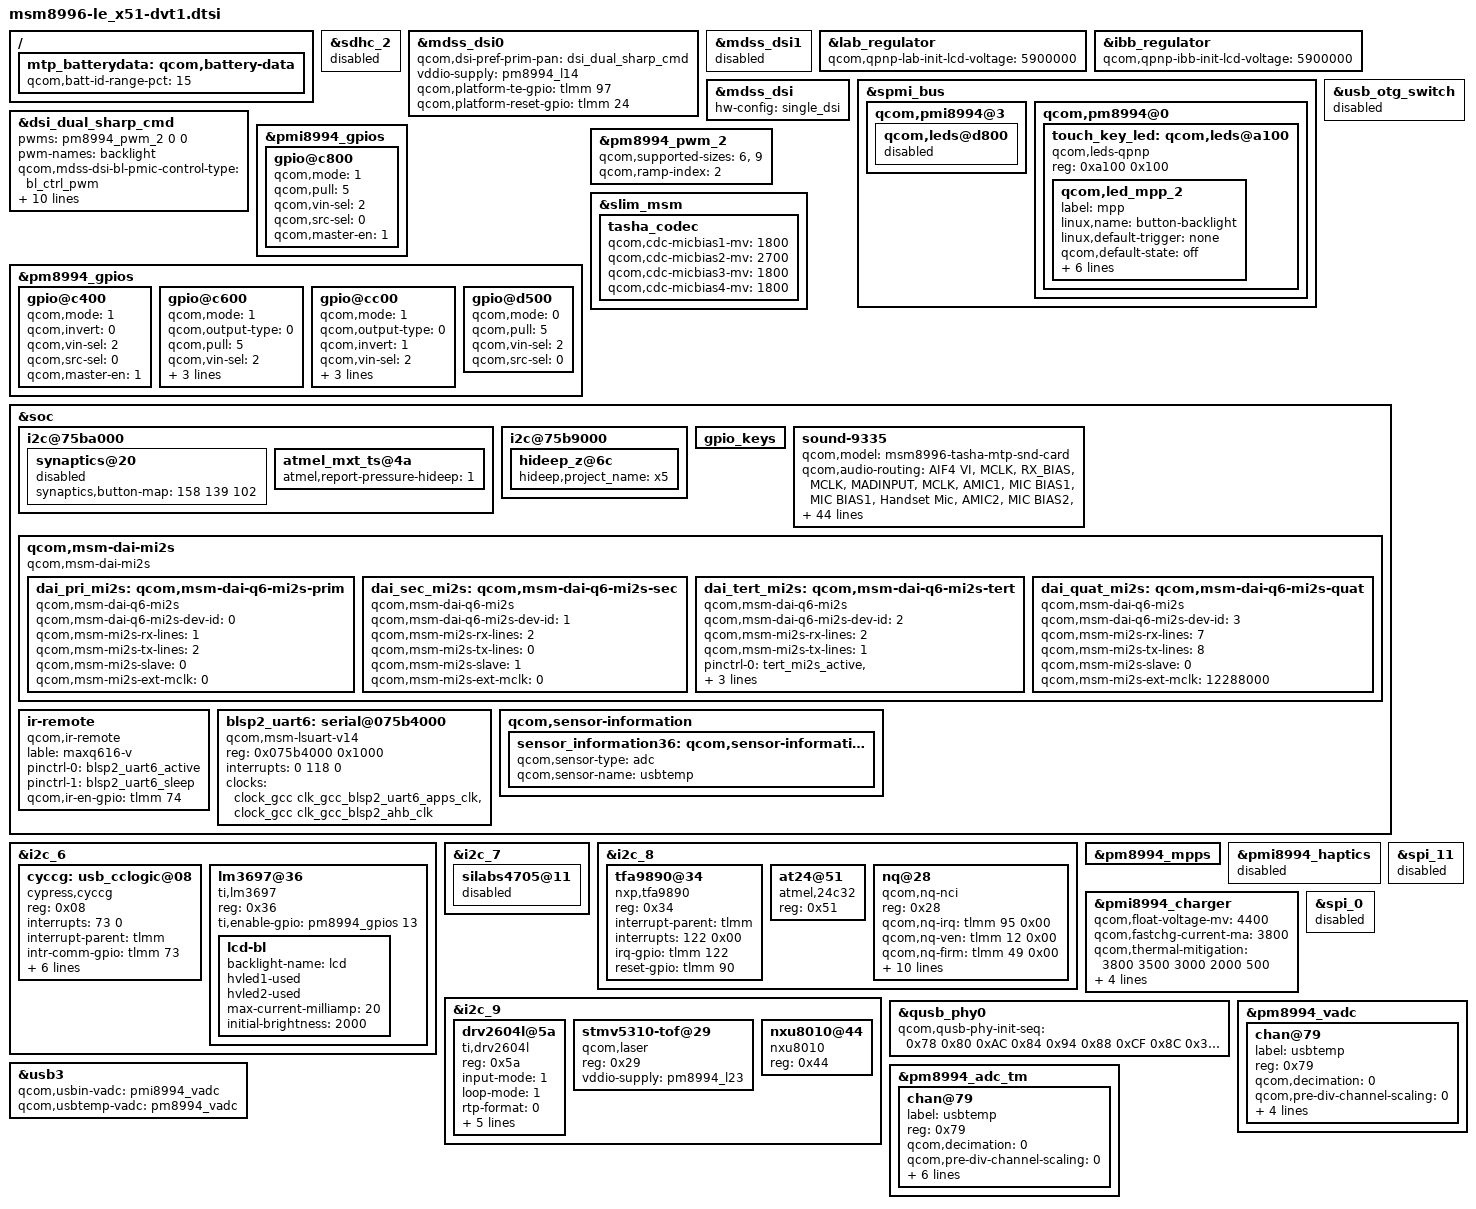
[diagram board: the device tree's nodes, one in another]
/* Copyright (c) 2015, The Linux Foundation. All rights reserved.
 *
 * This program is free software; you can redistribute it and/or modify
 * it under the terms of the GNU General Public License version 2 and
 * only version 2 as published by the Free Software Foundation.
 *
 * This program is distributed in the hope that it will be useful,
 * but WITHOUT ANY WARRANTY; without even the implied warranty of
 * MERCHANTABILITY or FITNESS FOR A PARTICULAR PURPOSE.  See the
 * GNU General Public License for more details.
 */

#include "msm8996-mtp.dtsi"
#include "msm8996-pinctrl-le_x51.dtsi"
#include "letv-tp-atmel_mxt_ts-le_x5-dvt1.dtsi"
#include "dsi-panel-sharp-dsc-cmd-le_x5-dvt1.dtsi"
#include "msm8996-camera-sensor-le_x5-dvt.dtsi"
#include "letv-ft-hideep-i2c.dtsi"

&sdhc_2 {
	status = "disabled";
};

&mdss_dsi0 {
	qcom,dsi-pref-prim-pan = <&dsi_dual_sharp_cmd>;
	vddio-supply = <&pm8994_l14>;
	qcom,platform-te-gpio = <&tlmm 97 0>;
	qcom,platform-reset-gpio = <&tlmm 24 0>;
	/delete-node/ qcom,platform-bklight-en-gpio;
};

&mdss_dsi1 {
	status = "disabled";
};

&lab_regulator {
	qcom,qpnp-lab-init-lcd-voltage = <5900000>;
};

&ibb_regulator {
	qcom,qpnp-ibb-init-lcd-voltage = <5900000>;
};

&mdss_dsi {
	hw-config = "single_dsi";
};

&spmi_bus {
	qcom,pmi8994@3 {
		qcom,leds@d800 {
			status = "disabled";
		};
	};

	qcom,pm8994@0 {
		/* configure pm8994 MPP2 as back-light of touch key */
		touch_key_led: qcom,leds@a100 {
			compatible = "qcom,leds-qpnp";
			reg = <0xa100 0x100>;
			status = "okay";

			qcom,led_mpp_2 {
				label = "mpp";
				linux,name = "button-backlight";
				linux,default-trigger = "none";
				qcom,default-state = "off";
				qcom,current-setting = <5>;
				qcom,max-current = <40>;
				qcom,id = <6>;
				qcom,source-sel = <1>;
				qcom,mode-ctrl = <0x60>; /* current sink mode */
				qcom,mode = "manual";
			};
		};
	};
};

&dsi_dual_sharp_cmd {
	pwms = <&pm8994_pwm_2 0 0>;
	pwm-names = "backlight";
	qcom,mdss-dsi-bl-pmic-control-type = "bl_ctrl_pwm";
	qcom,mdss-dsi-bl-pmic-bank-select = <0> ; //pm8996-bank#2
	qcom,mdss-dsi-pwm-gpio = <&pm8994_gpios 5 0>;
	qcom,mdss-dsi-bl-pmic-pwm-frequency = <100>;
	qcom,mdss-dsi-bl-min-level = <1>;
	qcom,mdss-dsi-bl-max-level = <2047>;
	qcom,cont-splash-enabled;
	qcom,panel-supply-entries = <&dsi_panel_pwr_supply>;

	qcom,mdss-dsi-panel-timings-8996 = [
		23 1f 07 09 05 03 04 a0
		23 1f 07 09 05 03 04 a0
		23 1f 07 09 05 03 04 a0
		23 1f 07 09 05 03 04 a0
		23 19 07 08 05 03 04 a0];
};

&usb_otg_switch {
	status = "disabled";
};

&pmi8994_gpios {
	/delete-node/ gpio@c000; /* PMI8994 GPIO 1 */
	/delete-node/ gpio@c100; /* PMI8994 GPIO 2 */
	/delete-node/ gpio@c200; /* PMI8994 GPIO 3 */
	/delete-node/ gpio@c300; /* PMI8994 GPIO 4 */
	/delete-node/ gpio@c400; /* PMI8994 GPIO 5 */
	/delete-node/ gpio@c600; /* PMI8994 GPIO 7 */
	/delete-node/ gpio@c700; /* PMI8994 GPIO 8 */
	/delete-node/ gpio@c900; /* PMI8994 GPIO 10 */

	gpio@c800 { /* GPIO 9 */ /* cclogic reset enable gpio */
		qcom,mode = <1>;
		qcom,pull = <5>;
		qcom,vin-sel = <2>;
		qcom,src-sel = <0>;
		qcom,master-en = <1>;
		status = "okay";
	};
};

&pm8994_gpios {
	/delete-node/ gpio@c200; /* PM8996 GPIO 3 */
	/delete-node/ gpio@c500; /* PM8996 GPIO 6 */
	/delete-node/ gpio@ca00; /* PM8996 GPIO 11 */
	/delete-node/ gpio@cb00; /* PM8996 GPIO 12 */
	/delete-node/ gpio@cd00; /* PM8996 GPIO 14 */
	gpio@c400 { /* GPIO 5 - lcd-pwm*/
		qcom,mode = <1>;
		qcom,invert = <0>;
		qcom,vin-sel = <2>;
		qcom,src-sel = <0>;
		qcom,master-en = <1>;
		status = "okay";
	};

	gpio@c600 { /* GPIO 7 - NFC DWL REQ */
		qcom,mode = <1>;
		qcom,output-type = <0>;
		qcom,pull = <5>;
		qcom,vin-sel = <2>;
		qcom,out-strength = <3>;
		qcom,src-sel = <0>;
		qcom,master-en = <1>;
		status = "okay";
	};

	gpio@cc00 { /* GPIO 13 - bl_en */
		qcom,mode = <1>;
		qcom,output-type = <0>;
		qcom,invert = <1>; 	/* output hight initially */
		qcom,vin-sel = <2>;
		qcom,out-strength = <1>;
		qcom,src-sel = <0>;
		qcom,master-en = <1>;
		status = "okay";
	};

	gpio@d500 { /* GPIO 22 */ /* cclogic cable interrupt gpio */
		qcom,mode = <0>;
		qcom,pull = <5>;
		qcom,vin-sel = <2>;
		qcom,src-sel = <0>;
		status = "okay";
	};
};

&pm8994_pwm_2 {
	qcom,supported-sizes = <6>, <9>;
	qcom,ramp-index = <2>;
	status = "okay";
};
&slim_msm {
	tasha_codec {
		qcom,cdc-micbias1-mv = <1800>;
		qcom,cdc-micbias2-mv = <2700>;
		qcom,cdc-micbias3-mv = <1800>;
		qcom,cdc-micbias4-mv = <1800>;

		/delete-node/ swr_master;
	};
};

&soc {
	i2c@75ba000 {
		synaptics@20 {
			status = "disabled";
			synaptics,button-map = <158 139 102>;
		};
		atmel_mxt_ts@4a {
			atmel,report-pressure-hideep = <1>;
		};
	};
	i2c@75b9000 {
		hideep_z@6c {
			status = "ok";
			hideep,project_name = "x5";
		};
	};

	/delete-node/ gen-vkeys;

	gpio_keys {
		/delete-node/ cam_focus;
	};

	/delete-node/ flash_led;

	sound-9335 {
		qcom,model = "msm8996-tasha-mtp-snd-card";

		qcom,audio-routing =
			"AIF4 VI", "MCLK",
			"RX_BIAS", "MCLK",
			"MADINPUT", "MCLK",
			"AMIC1", "MIC BIAS1",
			"MIC BIAS1", "Handset Mic",
			"AMIC2", "MIC BIAS2",
			"MIC BIAS2", "Headset Mic",
			"AMIC3", "MIC BIAS2",
			"MIC BIAS2", "USB Type-c Back Mic",
			"AMIC4", "MIC BIAS4",
			"MIC BIAS4", "REC ANC Analog Mic",
			"AMIC5", "MIC BIAS3",
			"MIC BIAS3", "ANC Analog Mic",
			"AMIC6", "MIC BIAS1",
			"MIC BIAS1", "Main Mic2";

		asoc-platform = <&pcm0>, <&pcm1>, <&pcm2>, <&voip>, <&voice>,
				<&loopback>, <&compress>, <&hostless>,
				<&afe>, <&lsm>, <&routing>, <&cpe>, <&compr>;
		asoc-platform-names = "msm-pcm-dsp.0", "msm-pcm-dsp.1", "msm-pcm-dsp.2",
				"msm-voip-dsp", "msm-pcm-voice", "msm-pcm-loopback",
				"msm-compress-dsp", "msm-pcm-hostless", "msm-pcm-afe",
				"msm-lsm-client", "msm-pcm-routing", "msm-cpe-lsm",
				"msm-compr-dsp";
		asoc-cpu = <&dai_pri_auxpcm>, <&dai_sec_auxpcm>, <&dai_hdmi>,
				<&dai_pri_mi2s>, <&dai_sec_mi2s>,
				<&dai_tert_mi2s>, <&dai_quat_mi2s>,
				<&sb_0_rx>, <&sb_0_tx>, <&sb_1_rx>, <&sb_1_tx>,
				<&sb_2_rx>, <&sb_2_tx>, <&sb_3_rx>, <&sb_3_tx>,
				<&sb_4_rx>, <&sb_4_tx>, <&sb_5_tx>, <&afe_pcm_rx>,
				<&afe_pcm_tx>, <&afe_proxy_rx>, <&afe_proxy_tx>,
				<&incall_record_rx>, <&incall_record_tx>,
				<&incall_music_rx>, <&incall_music2_rx>,
				<&sb_5_rx>, <&sb_6_rx>;
		asoc-cpu-names = "msm-dai-q6-auxpcm.1", "msm-dai-q6-auxpcm.2",
				"msm-dai-q6-hdmi.8",
				"msm-dai-q6-mi2s.0", "msm-dai-q6-mi2s.1",
				"msm-dai-q6-mi2s.2", "msm-dai-q6-mi2s.3",
				"msm-dai-q6-dev.16384", "msm-dai-q6-dev.16385",
				"msm-dai-q6-dev.16386", "msm-dai-q6-dev.16387",
				"msm-dai-q6-dev.16388", "msm-dai-q6-dev.16389",
				"msm-dai-q6-dev.16390", "msm-dai-q6-dev.16391",
				"msm-dai-q6-dev.16392", "msm-dai-q6-dev.16393",
				"msm-dai-q6-dev.16395", "msm-dai-q6-dev.224",
				"msm-dai-q6-dev.225", "msm-dai-q6-dev.241",
				"msm-dai-q6-dev.240", "msm-dai-q6-dev.32771",
				"msm-dai-q6-dev.32772", "msm-dai-q6-dev.32773",
				"msm-dai-q6-dev.32770", "msm-dai-q6-dev.16394",
				"msm-dai-q6-dev.16396";

		qcom,hdmi-audio-rx;
		letv,smartpa-audio;
		letv,hph_irq_detect = <0>;
		asoc-codec = <&stub_codec>, <&hdmi_audio>;
		asoc-codec-names = "msm-stub-codec.1", "msm-hdmi-audio-codec-rx";
		/delete-property/ qcom,hph-en1-gpio;
		/delete-property/ qcom,hph-en0-gpio;
		/delete-property/ qcom,us-euro-gpios;
		/delete-property/ qcom,wsa-devs;
		/delete-property/ qcom,wsa-aux-dev-prefix;
	};

	qcom,msm-dai-mi2s {
		compatible = "qcom,msm-dai-mi2s";
		dai_pri_mi2s: qcom,msm-dai-q6-mi2s-prim {
			compatible = "qcom,msm-dai-q6-mi2s";
			qcom,msm-dai-q6-mi2s-dev-id = <0>;
			qcom,msm-mi2s-rx-lines = <1>; /* SD0 (1 << 0) */
			qcom,msm-mi2s-tx-lines = <2>; /* SD1 (1 << 1) */
			qcom,msm-mi2s-slave = <0>;
			qcom,msm-mi2s-ext-mclk = <0>;
			/*pinctrl-names = "default", "idle";
			pinctrl-0 = <&pri_mi2s_active &pri_mi2s_mclk_active &pri_mi2s_sd0_active &pri_mi2s_sd1_active>;
			pinctrl-1 = <&pri_mi2s_sleep &pri_mi2s_mclk_sleep &pri_mi2s_sd0_sleep &pri_mi2s_sd1_sleep>;*/
		};
	};

	qcom,msm-dai-mi2s {
		compatible = "qcom,msm-dai-mi2s";
		dai_sec_mi2s: qcom,msm-dai-q6-mi2s-sec {
			compatible = "qcom,msm-dai-q6-mi2s";
			qcom,msm-dai-q6-mi2s-dev-id = <1>;
			qcom,msm-mi2s-rx-lines = <2>; /* SD0 (1 << 0) | SD1 (1 << 1) */
			qcom,msm-mi2s-tx-lines = <0>; /* None */
			qcom,msm-mi2s-slave = <1>;
			qcom,msm-mi2s-ext-mclk = <0>;
			/*pinctrl-names = "default", "idle";
			pinctrl-0 = <&sec_mi2s_active &sec_mi2s_mclk_active &sec_mi2s_sd0_active &sec_mi2s_sd1_active>;
			pinctrl-1 = <&sec_mi2s_sleep &sec_mi2s_mclk_sleep &sec_mi2s_sd0_sleep &sec_mi2s_sd1_sleep>;*/
		};
	};

	qcom,msm-dai-mi2s {
		compatible = "qcom,msm-dai-mi2s";
		dai_tert_mi2s: qcom,msm-dai-q6-mi2s-tert {
			compatible = "qcom,msm-dai-q6-mi2s";
			qcom,msm-dai-q6-mi2s-dev-id = <2>;
			qcom,msm-mi2s-rx-lines = <2>;
			qcom,msm-mi2s-tx-lines = <1>;
			pinctrl-names = "default", "sleep";
			pinctrl-0 = <&tert_mi2s_active &tert_mi2s_sd0_active &tert_mi2s_sd1_active>;
			pinctrl-1 = <&tert_mi2s_sleep &tert_mi2s_sd0_sleep &tert_mi2s_sd1_sleep>;
		};
	};

	qcom,msm-dai-mi2s {
		compatible = "qcom,msm-dai-mi2s";
		dai_quat_mi2s: qcom,msm-dai-q6-mi2s-quat {
			compatible = "qcom,msm-dai-q6-mi2s";
			qcom,msm-dai-q6-mi2s-dev-id = <3>;
			qcom,msm-mi2s-rx-lines = <7>; /* SD0 (1 << 0) | SD1 (1 << 1) | SD2 (1 << 2) */
			qcom,msm-mi2s-tx-lines = <8>; /* SD2 (1 << 3) */
			qcom,msm-mi2s-slave = <0>;
			qcom,msm-mi2s-ext-mclk = <12288000>;
			/*pinctrl-names = "default", "idle";
			pinctrl-0 = <&quat_mi2s_active &quat_mi2s_mclk_active &quat_mi2s_sd0_active &quat_mi2s_sd1_active &quat_mi2s_sd2_active &quat_mi2s_sd3_active>;
			pinctrl-1 = <&quat_mi2s_sleep &quat_mi2s_mclk_sleep &quat_mi2s_sd0_sleep &quat_mi2s_sd1_sleep &quat_mi2s_sd2_sleep &quat_mi2s_sd3_sleep>;*/
		};
	};

        ir-remote {
                compatible = "qcom,ir-remote";
                lable = "maxq616-v";
                pinctrl-names = "ir_active", "ir_sleep";
                pinctrl-0 = <&blsp2_uart6_active>;
                pinctrl-1 = <&blsp2_uart6_sleep>;
                qcom,ir-en-gpio = <&tlmm 74 0>;
        };

        blsp2_uart6: serial@075b4000 {
                compatible = "qcom,msm-lsuart-v14";
                reg = <0x075b4000 0x1000>;
                interrupts = <0 118 0>;
                status = "disabled";

                clock-names = "core_clk", "iface_clk";
                clocks = <&clock_gcc clk_gcc_blsp2_uart6_apps_clk>,
                 <&clock_gcc clk_gcc_blsp2_ahb_clk>;
        };
};

&blsp2_uart6 {
        status = "ok";
};

&i2c_6 {
	cyccg: usb_cclogic@08 {        /* The I2C bus that CCG2 connected to */
		status = "ok";
		compatible = "cypress,cyccg";
		reg = <0x08>;                    /* CCG2 I2C address: 0x08*/
		interrupts = <73 0>;            /* CCG2 interrupt line GPIO: 73*/
		interrupt-parent = <&tlmm>;      /* CCG2 interrupt line GPIO controller */
		intr-comm-gpio = <&tlmm 73 0x0>;
		reset-gpio = <&pmi8994_gpios 9 0x0>;
		ad-sel-gpio = <&tlmm 25 0x0>;
		uart-sw-gpio = <&tlmm 83 0x0>;
		pmi8994_boost_5v-supply = <&pmi8994_boost_5v>;
		external-5v-en-gpio = <&tlmm 39 0x0>;
		external-5v-en-flag;
	};

	lm3697@36 {
		status = "okay";
		compatible = "ti,lm3697";
		reg = <0x36>;

		ti,enable-gpio = <&pm8994_gpios 13 0>;

		lcd-bl {
			backlight-name = "lcd";
			hvled1-used;
			hvled2-used;
			//hvled3-used;

			max-current-milliamp = <20>;
			initial-brightness = <2000>;
			//pwm-period = <10000>;
		};
	};
};

&i2c_7 {
	silabs4705@11 { /* SiLabs FM chip, slave id 0x11*/
		status = "disabled";
	};
};

&i2c_8 {
	tfa9890@34 { /* tfa9890 smartpa device */
		compatible = "nxp,tfa9890";
		reg = <0x34>;
		interrupt-parent = <&tlmm>;
		interrupts = <122 0x00>;
		irq-gpio = <&tlmm 122 0x00>;
		reset-gpio = <&tlmm 90 0x00>;
	};

	at24@51 {
		compatible = "atmel,24c32";
		reg = <0x51>;
	};
};

&pm8994_mpps {
	/* Remove pm8994 MPP2 reference function, because it is
	configured as back-light of touch key */
	/delete-node/ mpp@a100; /* MPP 2 */
	/delete-node/ mpp@a700; /* MPP 8 */
};

/*haptics start*/
&pmi8994_haptics {
	status = "disabled";
};

&i2c_8 {
	nq@28 {
		compatible = "qcom,nq-nci";
		reg = <0x28>;
		qcom,nq-irq = <&tlmm 95 0x00>;
		qcom,nq-ven = <&tlmm 12 0x00>;
		qcom,nq-firm = <&tlmm 49 0x00>;
		qcom,nq-clkreq = <&pm8994_gpios 10 0x00>;
		nxp,p61-pwr = <&pm8994_gpios 7 0x00>;
		nxp,p61-rst = <&tlmm 40 0>;
		interrupt-parent = <&tlmm>;
		qcom,clk-src = "BBCLK2";
		interrupts = <95 0>;
		interrupt-names = "nfc_irq";
		pinctrl-names = "nfc_active", "nfc_suspend";
		pinctrl-0 = <&nfc_int_active &nfc_disable_active>;
		pinctrl-1 = <&nfc_int_suspend &nfc_disable_suspend>;
		clocks = <&clock_gcc clk_bb_clk2_pin>;
		clock-names = "ref_clk";
	};
};

&i2c_9 {
	drv2604l@5a {
		status = "ok";
		compatible = "ti,drv2604l";
		reg = <0x5a>;
		input-mode = <1>;
		loop-mode = <1>;
		rtp-format = <0>;
		actuator-type = <1>;
		frequency = <204>;
		vib-rated-mv = <2000>;
		vib-overdrive-mv = <2500>;
		enable-gpio = <&tlmm 38 0>;
	};
        stmv5310-tof@29 {
                compatible = "qcom,laser";
                reg = <0x29>;
                vddio-supply = <&pm8994_l23>;
        };
        nxu8010@44 {
                compatible = "nxu8010";
                reg = <0x44>;
        };
};
/*haptics end*/

/{
	mtp_batterydata: qcom,battery-data {
		qcom,batt-id-range-pct = <15>;
		#include "batterydata-le-x5-3700mah.dtsi"
	};
};

&pmi8994_charger {
	qcom,float-voltage-mv = <4400>;
	qcom,fastchg-current-ma = <3800>;
	qcom,thermal-mitigation = <3800 3500 3000 2000 500>;
	qcom,usb-thermal-mitigation = <3000 2000 1000 0>;
	qcom,fastchg-current-comp = <1200>;
	qcom,float-voltage-comp = <16>;
	qcom,ignore_otgid;
};

&qusb_phy0 {
        qcom,qusb-phy-init-seq = <0x78 0x80
                                0xAC 0x84
                                0x94 0x88
                                0xCF 0x8C
                                0x30 0x08
                                0x79 0x0C
                                0x21 0x10
                                0x14 0x9C
                                0x80 0x04
                                0x9F 0x1C
                                0x00 0x18>;
};
&spi_11 {
	status = "disabled";
};

&spi_0 { /* BLSP1 QUP1 */
	status = "disabled";
};

&usb3 {
	qcom,usbin-vadc = <&pmi8994_vadc>;
	qcom,usbtemp-vadc = <&pm8994_vadc>;
};

&pm8994_vadc {
	chan@79 {
		label = "usbtemp";
		reg = <0x79>;
		qcom,decimation = <0>;
		qcom,pre-div-channel-scaling = <0>;
		qcom,calibration-type = "ratiometric";
		qcom,scale-function = <2>;
		qcom,hw-settle-time = <2>;
		qcom,fast-avg-setup = <0>;
	};
};

&pm8994_adc_tm {
	chan@79 {
		label = "usbtemp";
		reg = <0x79>;
		qcom,decimation = <0>;
		qcom,pre-div-channel-scaling = <0>;
		qcom,calibration-type = "ratiometric";
		qcom,scale-function = <2>;
		qcom,hw-settle-time = <2>;
		qcom,fast-avg-setup = <0>;
		qcom,btm-channel-number = <0x88>;
		qcom,thermal-node;
	};
};

&soc {
	qcom,sensor-information {
		sensor_information36: qcom,sensor-information-36 {
			qcom,sensor-type = "adc";
			qcom,sensor-name = "usbtemp";
		};
	};
};
